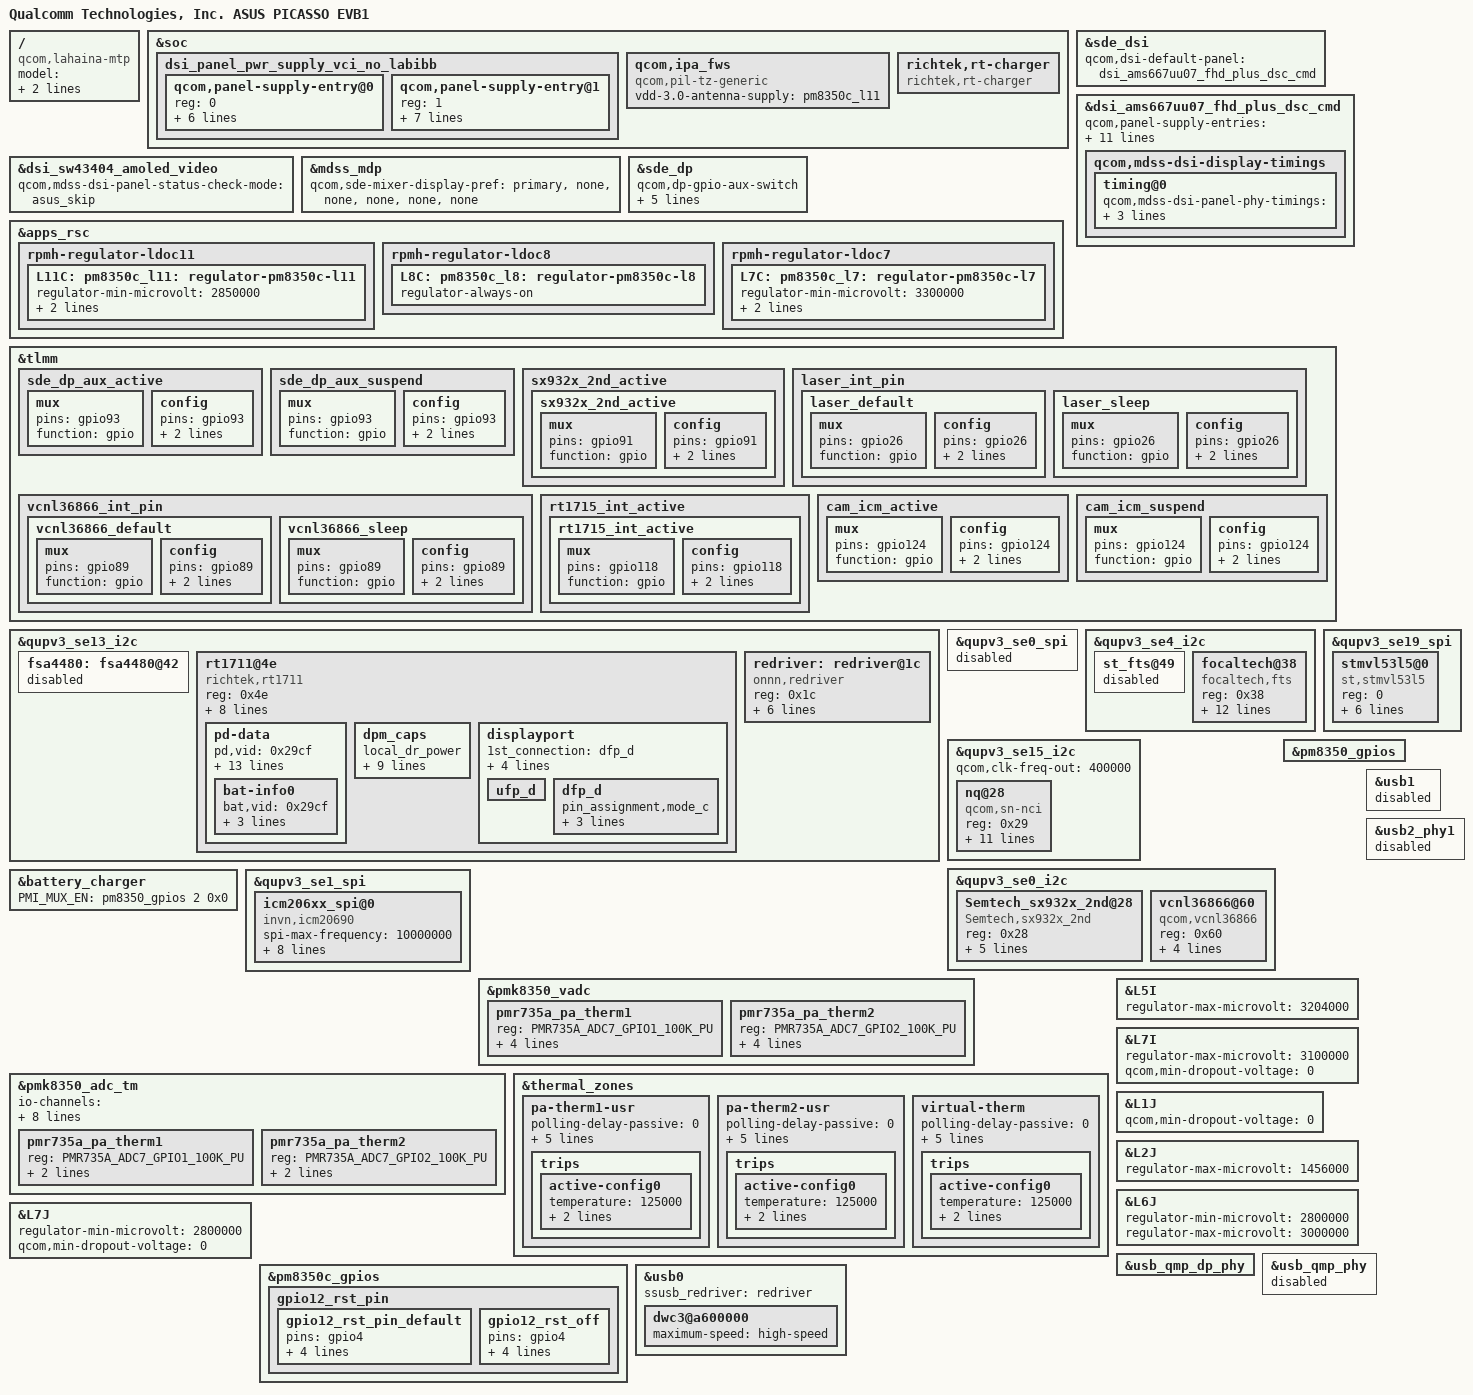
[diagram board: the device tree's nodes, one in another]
/dts-v1/;
/plugin/;

#include "lahaina-mtp.dtsi"
/* ASUS BSP Display +++ */
#include "dsi-panel-ams667uu07-fhd-plus-dsc-cmd.dtsi"

/* ASUS BSP Camera +++ */
#include "camera/zs675kw-picasso-camera-sensor-mtp.dtsi"



/ {
	model = "Qualcomm Technologies, Inc. ASUS PICASSO EVB1";
	compatible = "qcom,lahaina-mtp", "qcom,lahaina", "qcom,mtp";
	qcom,board-id = <35 0>;
};

/*   ====================================
*    overlay for display - start
*    ====================================
*/
&soc {
	dsi_panel_pwr_supply_vci_no_labibb: dsi_panel_pwr_supply_vci_no_labibb {
		#address-cells = <1>;
		#size-cells = <0>;

		qcom,panel-supply-entry@0 {
			reg = <0>;
			qcom,supply-name = "vddio";
			qcom,supply-min-voltage = <1800000>;
			qcom,supply-max-voltage = <1800000>;
			qcom,supply-enable-load = <60700>;
			qcom,supply-disable-load = <80>;
			qcom,supply-post-on-sleep = <20>;
		};

		qcom,panel-supply-entry@1 {
			reg = <1>;
			qcom,supply-name = "vdd";
			qcom,supply-min-voltage = <3000000>;
			qcom,supply-max-voltage = <3000000>;
			qcom,supply-enable-load = <10000>;
			qcom,supply-disable-load = <0>;
			qcom,supply-post-on-sleep = <0>;
			qcom,supply-pre-off-sleep = <10>;
		};
	};

};

&sde_dsi {
	/delete-property/ avdd-supply;
	qcom,dsi-default-panel = <&dsi_ams667uu07_fhd_plus_dsc_cmd>;

};

&dsi_ams667uu07_fhd_plus_dsc_cmd {
	qcom,panel-supply-entries = <&dsi_panel_pwr_supply_vci_no_labibb>;
	qcom,mdss-dsi-bl-pmic-control-type = "bl_ctrl_dcs";
	qcom,mdss-dsi-bl-min-level = <1>;
	qcom,mdss-dsi-bl-max-level = <4095>;

	qcom,platform-te-gpio = <&tlmm 82 0>; // default is 82
	qcom,platform-reset-gpio = <&tlmm 24 0>;
	qcom,platform-en-gpio = <&tlmm 80 0>;

	qcom,ulps-enabled;
	qcom,dsi-select-clocks = "mux_byte_clk0", "mux_pixel_clk0";
	qcom,mdss-dsi-display-timings {
		timing@0 {
			qcom,mdss-dsi-panel-phy-timings = [00 14 05 05 13 1E 05
				05 06 02 04 00 12 0A];
			qcom,display-topology = <2 2 1>;
			qcom,default-topology-index = <0>;
		};
	};
};

&dsi_sw43404_amoled_video {
	qcom,mdss-dsi-panel-status-check-mode = "asus_skip";
};

&mdss_mdp {
	qcom,sde-mixer-display-pref = "primary", "none", "none",
				"none", "none", "none";
};

&sde_dp {
	/delete-property/ qcom,dp-aux-switch;
	qcom,dp-gpio-aux-switch;

	qcom,aux-en-gpio = <&tlmm 93 0>;
	qcom,aux-sel-gpio = <&pm8350c_gpios 1 0x0>;
	qcom,audio-debug-gpio = <&tlmm 123 0>;

	pinctrl-names = "mdss_dp_active", "mdss_dp_sleep";
	pinctrl-0 = <&sde_dp_aux_active >;
	pinctrl-1 = <&sde_dp_aux_suspend>;
};

//ASUS_BSP RIL+++
&soc {
	qcom,ipa_fws {
		compatible = "qcom,pil-tz-generic";
		vdd-3.0-antenna-supply = <&pm8350c_l11>;
	};
};

&apps_rsc {
	rpmh-regulator-ldoc11 {
		L11C: pm8350c_l11: regulator-pm8350c-l11 {
			regulator-min-microvolt = <2850000>;
			regulator-max-microvolt = <2850000>;
			qcom,init-voltage = <2850000>;
		};
	};
};
//ASUS_BSP RIL---

&tlmm {
	/delete-property/ display_panel_avdd_default;

	sde_dp_aux_active: sde_dp_aux_active {
		mux {
			pins = "gpio93";
			function = "gpio";
		};

		config {
			pins = "gpio93";
			bias-disable = <0>; /* no pull */
			drive-strength = <8>;
		};
	};

	sde_dp_aux_suspend: sde_dp_aux_suspend {
		mux {
			pins = "gpio93";
			function = "gpio";
		};

		config {
			pins = "gpio93";
			bias-disable = <0>; /* no pull */
			drive-strength = <2>;
		};
	};
};

&qupv3_se13_i2c {
	fsa4480: fsa4480@42 {
		status = "disable";
	};
};
/*   ====================================
*    overlay for display - end
*    ====================================
*/

/*    ====================================
 *    overlay for lahainap-v2.dtsi - start
 *    ====================================
 */

/*    ====================================
 *    overlay for lahainap-v2.dtsi - end
 *    ====================================
 */



/*    ====================================
 *    overlay for lahainap.dtsi - start
 *    ====================================
 */

/*    ====================================
 *    overlay for lahainap.dtsi - end
 *    ====================================
*/



/*    ====================================
 *    overlay for lahaina-mtp.dtsi - start
 *    ====================================
 */

&qupv3_se0_spi {
	status = "disable";
};

//ASUS_BSP BerylHou +++ 
//"touch FT3658U" +++
 &qupv3_se4_i2c {
  	status = "ok";

  	st_fts@49 {
		status = "disable";
	};
  	
	focaltech@38 {
		compatible = "focaltech,fts";
		reg = <0x38>;
		interrupt-parent = <&tlmm>;
		interrupts = <23 0x2008>;
		focaltech,reset-gpio = <&tlmm 22 0x00>;
		focaltech,irq-gpio = <&tlmm 23 0x2008>;
		focaltech,vddio = <&tlmm 131 0x00>;
		focaltech,max-touch-number = <10>;
		focaltech,display-coords = <0 0 1080 2400>;

		vdd-supply = <&L3C>;
		vcc_i2c-supply = <&L8C>;

		pinctrl-names = "pmx_ts_active", "pmx_ts_suspend","pmx_ts_release";
		pinctrl-0 = <&ts_active>;
		pinctrl-1 = <&ts_int_suspend &ts_reset_suspend>;
		pinctrl-2 = <&ts_release>;

//		panel = <&dsi_ams667uu07_fhd_plus_dsc_cmd>;
//			 &dsi_r66451_amoled_video>;
	};
};
//"touch FT3658U" ---

&qupv3_se15_i2c{
	status = "ok";
	qcom,clk-freq-out = <400000>;

	nq@28 {
		compatible = "qcom,sn-nci";
		reg = <0x29>;
		qcom,sn-irq = <&tlmm 87 0x00>;
		qcom,sn-ven = <&tlmm 62 0x00>;
		qcom,sn-firm = <&tlmm 86 0x00>;
		qcom,sn-clkreq = <&tlmm 63 0x00>;
		interrupt-parent = <&tlmm>;
		interrupts = <87 0>;
		interrupt-names = "nfc_irq";
		pinctrl-names = "nfc_active", "nfc_suspend";
		pinctrl-0 = <&nfc_int_active &nfc_enable_active
				&nfc_clk_req_active &nfc_fwdl_active>;
		pinctrl-1 = <&nfc_int_suspend &nfc_enable_suspend
				&nfc_clk_req_suspend &nfc_fwdl_suspend>;
	};
};


//cap sensor 1  SX9325" +++
/* &qupv3_se15_i2c{
	status = "ok";
	Semtech_sx932x@28 {
	compatible = "Semtech,sx932x";
	reg = <0x28>;
	//interrupt-parent = <&tlmm>;
	//interrupts = <99 0>;
	pinctrl-names = "sx932x_1st_active";
	pinctrl-0 = <&sx932x_1st_active>;
		
	Semtech,nirq-gpio = <&tlmm 99 0x00>;
	status = "ok";
	Semtech,reg-num = <45>; // total registers number to initialize
	Semtech,reg-init  = /bits/ 8 < 0x10 0x1C
                                0x11 0x21
                                0x14 0x00
                                0x15 0x00
                                0x20 0x20
                                0x23 0x00
                                0x24 0x47
                                0x26 0x00
                                0x27 0x47
                                0x28 0x39
                                0x29 0x2D
                                0x2A 0x36
                                0x2B 0x07
                                0x2C 0x12
                                0x2D 0x08
                                0x30 0x21
                                0x31 0x0B
                                0x32 0x20
                                0x33 0x20
                                0x34 0x0C
                                0x35 0x00
                                0x36 0x8E
                                0x37 0xB3
                                0x40 0x00
                                0x41 0x00
                                0x42 0x00
                                0x43 0x00
                                0x44 0x00
                                0x45 0x05
                                0x46 0x00
                                0x47 0x00
                                0x48 0x00
                                0x49 0x00
                                0x4A 0x00
                                0x4B 0x00
                                0x4C 0x00
                                0x50 0x14
                                0x51 0x70
                                0x52 0x20
                                0x02 0x00
                                0x05 0x6F
                                0x06 0x00
                                0x07 0x80
                                0x08 0x01
                                0x03 0x0F>;
	};
 };
 
 &tlmm{
	sx932x_active {
		sx932x_1st_active: sx932x_1st_active {
			mux {
				pins = "gpio99";
				function = "gpio";
			};
			config {
				pins = "gpio99";
				bias-pull-up;
				drive-strength = <6>;
			};
		};
	};
  };
*/
//"cap sensor 1  SX9325" ---
//"cap sensor 2  SX9325" +++
 &qupv3_se0_i2c{
	status = "ok";
	Semtech_sx932x_2nd@28 {
	compatible = "Semtech,sx932x_2nd";
	reg = <0x28>;
	pinctrl-names = "sx932x_2nd_active";
	pinctrl-0 = <&sx932x_2nd_active>;
		
	Semtech,nirq-gpio = <&tlmm 91 0x00>;
	status = "ok";	/**/
	Semtech,reg-num = <45>; /* total registers number to initialize*/
	Semtech,reg-init  = /bits/ 8 < 0x10 0x1C
                                0x11 0x21
                                0x14 0x00
                                0x15 0x00
                                0x20 0x20
                                0x23 0x00
                                0x24 0x47
                                0x26 0x00
                                0x27 0x47
                                0x28 0x39
                                0x29 0x2D
                                0x2A 0x36
                                0x2B 0x07
                                0x2C 0x12
                                0x2D 0x08
                                0x30 0x21
                                0x31 0x0B
                                0x32 0x20
                                0x33 0x20
                                0x34 0x0C
                                0x35 0x00
                                0x36 0x8E
                                0x37 0xB3
                                0x40 0x00
                                0x41 0x00
                                0x42 0x00
                                0x43 0x00
                                0x44 0x00
                                0x45 0x05
                                0x46 0x00
                                0x47 0x00
                                0x48 0x00
                                0x49 0x00
                                0x4A 0x00
                                0x4B 0x00
                                0x4C 0x00
                                0x50 0x14
                                0x51 0x70
                                0x52 0x20
                                0x02 0x00
                                0x05 0x6F
                                0x06 0x00
                                0x07 0x80
                                0x08 0x01
                                0x03 0x0F>;
	};
};

&tlmm{
	sx932x_2nd_active {
		sx932x_2nd_active: sx932x_2nd_active {
			mux {
				pins = "gpio91";
				function = "gpio";
			};
			config {
				pins = "gpio91";
				bias-pull-up;
				drive-strength = <6>;
			};
		};
	};
};
//"cap sensor 2  SX9325" ---
//ASUS_BSP BerylHou --- 

//[+++] ASUS_BSP : Add for battery_charger
&battery_charger {
	PMI_MUX_EN = <&pm8350_gpios 2 0x0>;
};
//[---] ASUS_BSP : Add for battery_charger

// ASUS_BSP +++ ShowCai laser sensor stmvl53l5
&qupv3_se19_spi {
        status = "ok";
        stmvl53l5@0 {
                compatible = "st,stmvl53l5";
                reg = <0>;
                spi-max-frequency = <20000000>;
                laser_vdd-supply = <&pm8350c_l7>;
                laser_bus-supply = <&pm8350c_l8>;
                pinctrl-names = "laser_default", "laser_suspend";
                pinctrl-0 = <&laser_default>;
                pinctrl-1 = <&laser_sleep>;
                qcom,intr-gpio = <&tlmm 26 0x0>;
        };
};
&tlmm {
        laser_int_pin {
                laser_default: laser_default {
                        mux {
                                pins = "gpio26";
                                function = "gpio";
                        };
                                config {
                                pins = "gpio26";
                                bias-pull-up; /* No PULL */
                                drive-strength = <8>; /* 2 MA */
                        };
                };
                laser_sleep: laser_sleep {
                        mux {
                                pins = "gpio26";
                                function = "gpio";
                        };
                                config {
                                pins = "gpio26";
                                bias-pull-down; /* PULL DOWN */
                                drive-strength = <2>; /* 2 MA */
                        };
                };
        };
};
// ASUS_BSP --- ShowCai laser sensor stmvl53l5

// ASUS_BSP +++ ClayWang vcnl36866
&qupv3_se0_i2c {
        status = "ok";
            vcnl36866@60 {
			compatible = "qcom,vcnl36866";
			reg = <0x60>;
			pinctrl-names = "alsps_gpio_high","alsps_gpio_low";
			pinctrl-0 = <&vcnl36866_default>;
			pinctrl-1 = <&vcnl36866_sleep>;
			qcom,alsps-gpio = <&tlmm 89 0x0>;
			vcc_psensor-supply = <&pm8350c_l7>;
			
		};
};

&apps_rsc {
	// ASUS BSP +++ Clay vcnl36866
	rpmh-regulator-ldoc8 {
		L8C: pm8350c_l8: regulator-pm8350c-l8 {
			regulator-always-on;	/* ASUS BSP Always Enable 1.8V for I2C & Sensors */
		};
	};

	rpmh-regulator-ldoc7 {
		L7C: pm8350c_l7: regulator-pm8350c-l7 {
			regulator-min-microvolt = <3300000>;
			regulator-max-microvolt = <3300000>;
			qcom,init-voltage = <3300000>;
		};
	};
	// ASUS BSP --- Clay vcnl36866
};

&tlmm {	
	// ASUS_BSP +++ ClayWang vcnl36866
	vcnl36866_int_pin {
		vcnl36866_default: vcnl36866_default {
			mux {
				pins = "gpio89";
				function = "gpio";
			};
				config {
				pins = "gpio89";
				bias-pull-up;
				drive-strength = <6>;
			};
		};
			vcnl36866_sleep: vcnl36866_sleep {
			mux {
				pins = "gpio89";
				function = "gpio";
			};
				config {
				pins = "gpio89";
				bias-pull-up;
				drive-strength = <6>;
			};
		};
	};
	// ASUS_BSP --- ClayWang vcnl36866
};
// ASUS_BSP --- ClayWang vcnl36866

//ASUS BSP Richtek TypeC PD +++
&qupv3_se13_i2c {
	status = "ok";
	rt1711@4e {
		compatible = "richtek,rt1711";
		reg = <0x4e>;
		rt1711,irq_pin = <&tlmm 118 0x00>;
		rt-dual,supported_modes = <0>; /* 0: dfp/ufp, 1: dfp, 2: ufp */
		rt-tcpc,name = "type_c_port0"; /* tcpc_device's name */
		rt-tcpc,role_def = <4>; /* 0: SNK Only, 1: SRC Only, 2: DRP, 3: Try.SRC, 4: Try.SNK */
		rt-tcpc,rp_level = <0>; /* 0: Default, 1: 1.5, 2: 3.0 */
		rt-tcpc,vconn_supply  = <1>;  /* 0: Never, 1: Always, 2: EMarkOnly, 3: StartOnly */
		rt-tcpc,notifier_supply_num = <1>; /* the number of notifier supply */
		pinctrl-names = "rt1715_int_active";
		pinctrl-0 = <&rt1715_int_active>;
		pd-data {
			pd,vid = <0x29cf>;
			pd,pid = <0x5081>;
			pd,source-cap-ext = <0x171129cf 0x00000000 0x00000102 0x00000000 0x00000000 0x02000000>;
			pd,mfrs = "RichtekTCPC";

			/*
			 *	VSAFE5V = 0, MAX_POWER = 1, CUSTOM = 2,
			 *	MAX_POWER_LV = 0x21, MAX_POWER_LVIC = 0x31
			 *	MAX_POWER_HV = 0x41, MAX_POWER_HVIC = 0x51
			 */
				pd,charging_policy= <0x21>;

			/*
			 * Fixed 5V, 500 mA <0x00019032>
			 * Fixed 5V, 1A <0x00019064>
			 * Fixed 5V, 2A <0x000190c8>
			 * Fixed 5V, 3A <0x0001912c>
			 * Fixed 9V, 500 mA <0x0002d032>
			 * Fixed 9V, 1A <0x0002d064>
			 * Fixed 9V, 2A <0x0002d0c8>
			 * Fixed 9V, 3A <0x0002d12c>
			 * Variable 5-9V, 1A <0x8642d064>
			 * Variable 5-9V, 2A <0x8642d0c8>
			 * Variable 5-9V, 3A <0x8642d12c>
			 * PPS 3V~5.9V, 3A <0xC0761E3C>
			 */
				pd,source-pdo-size = <1>;
				pd,source-pdo-data = <0x00019032>; /* 5V, 500 mA */
				pd,sink-pdo-size = <2>;
				pd,sink-pdo-data = <0x000190c8 0x000190c8> ;   /* 0x0002d0c8 : 9V, 2A<0x04019032 0x04019064> */

			/*
			 * No DP, host + device
			 *	pd,id-vdo-size = <3>;
					pd,id-vdo-data = <0xd00029cf 0x0 0x00010000>;
			 * With DP
			 *	pd,id-vdo-size = <4>;
					pd,id-vdo-data = <0xec0029cf 0x0 0x00010000 0x11000001>;
			 */

				pd,id-vdo-size = <3>;
				pd,id-vdo-data = <0xd00029cf 0x0 0x00010000>;

			bat,nr = <1>;
			pd,country_nr = <0>;

			bat-info0 {
				bat,vid = <0x29cf>;
				bat,pid = <0x1711>;
				bat,mfrs = "bat1";
				bat,design_cap = <3000>;
			};

			//bat-info1 {
			//	bat,vid = <0x8abc>;
			//	bat,pid = <0x5234>;
			//	bat,mfrs = "bat2";
			//	bat,design_cap = <4000>;
			//};

			//country0 {
			//	pd,country_code = <0x5457>;
			//	pd,country_len = <2>; /* max len = 26 */
			//	pd,country_data = <0xff 0xff>;
			//};

			//country1 {
			//	pd,country_code = <0x5553>;
			//	pd,country_len = <3>; /* max len = 26 */
			//	pd,country_data = <0xf1 0xf2 0xf3>;
			//};
		};

		dpm_caps {
			local_dr_power;
			local_dr_data;
			//local_ext_power;
			local_usb_comm;
			//local_usb_suspend;
			//local_high_cap;
			//local_give_back;
			local_no_suspend;
			local_vconn_supply;

			//attemp_discover_cable_dfp;
			attemp_enter_dp_mode;
			//attemp_discover_cable;
			attemp_discover_id;
			/* 0: disable, 1: prefer_snk, 2: prefer_src */
			pr_check = <0>;
			//pr_reject_as_source;
			//pr_reject_as_sink;
			pr_check_gp_source;
			//pr_check_gp_sink;

			/* 0: disable, 1: prefer_ufp, 2: prefer_dfp */
			dr_check = <0>;
			//dr_reject_as_dfp;
			//dr_reject_as_ufp;
		};
		displayport {
			/* connection type = "both", "ufp_d", "dfp_d" */
			1st_connection = "dfp_d";
			2nd_connection = "dfp_d";
			signal,dp_v13;
			//signal,dp_gen2;
			usbr20_not_used;
			typec,receptacle;
			ufp_d {
				//pin_assignment,mode_a;
				//pin_assignment,mode_b;
				//pin_assignment,mode_c;
				//pin_assignment,mode_d;
				//pin_assignment,mode_e;
			};
			dfp_d {
				/* Only support mode C & D */
				//pin_assignment,mode_a;
				//pin_assignment,mode_b;
				pin_assignment,mode_c;
				pin_assignment,mode_d;
				pin_assignment,mode_e;
				pin_assignment,mode_f;
			};
		};
	};
};


/* ASUS_BSP +++ icm20690 */
&qupv3_se1_spi {
	status = "ok";
        icm206xx_spi@0 {
                spi-max-frequency = <10000000>;
                compatible = "invn,icm20690";
                reg = <0x0>;
                invn,gpio-int = <&tlmm 7 1>;
                invn,use-interrupt;
                invn,place = "Portrait Down Back Side";
                icm206xx-supply = <&pm8008j_l7>;
                icm206xx-vdd-supply = <&pm8008j_l5>;
                pinctrl-names = "cam_default", "cam_suspend";
                pinctrl-0 = <&cam_icm_active>;
                pinctrl-1 = <&cam_icm_suspend>;
        };
};
/* ASUS_BSP --- icm20690 */

&soc {
	richtek,rt-charger {
	    compatible = "richtek,rt-charger";
	    //vconn-supply = <&vconn_5v>;
	};
};
//ASUS BSP Richtek TypeC PD ---

&tlmm {
	//ASUS BSP Richtek TypeC PD +++
	rt1715_int_active {
		rt1715_int_active: rt1715_int_active {
			mux {
				pins = "gpio118";
				function = "gpio";
			};

			config {
				pins = "gpio118";
				drive-strength = <2>;
				bias-pull-up;
			};
		};
	};
	//ASUS BSP Richtek TypeC PD ---
	/* ASUS_BSP +++ icm20690 */
	cam_icm_active: cam_icm_active {
		mux {
			pins = "gpio124";
			function = "gpio";
		};

		config {
			pins = "gpio124";
			bias-pull-up;
			drive-strength = <8>;
		};
	};

	cam_icm_suspend: cam_icm_suspend {
		mux {
			pins = "gpio124";
			function = "gpio";
		};

		config {
			pins = "gpio124";
			bias-pull-down;
			drive-strength = <2>; 
		};
	};
	/* ASUS_BSP --- icm20690 */
};

&qupv3_se13_i2c {
	status = "ok";

	redriver: redriver@1c {
		compatible = "onnn,redriver";
		reg = <0x1c>;

		pinctrl-names = "enable_gpio";
		pinctrl-0 = <&usb3phy_portselect_gpio>;
		orientation_gpio = <&tlmm 81 0>;

		eq = /bits/ 8 <
				/* Parameters for USB */
				0x4 0x4 0x4 0x4
				/* Parameters for DP */
				0x6 0x4 0x4 0x6>;
		flat-gain = /bits/ 8 <
				/* Parameters for USB */
				0x3 0x1 0x1 0x3
				/* Parameters for DP */
				0x2 0x1 0x1 0x2>;
		output-comp = /bits/ 8 <
				/* Parameters for USB */
				0x3 0x3 0x3 0x3
				/* Parameters for DP */
				0x3 0x3 0x3 0x3>;
		loss-match = /bits/ 8 <
				/* Parameters for USB */
				0x1 0x3 0x3 0x1
				/* Parameters for DP */
				0x3 0x3 0x3 0x3>;
	};
};

/*    ====================================
 *    overlay for lahaina-mtp.dtsi - end
 *    ====================================
 */


/*    ====================================
 *    overlay for lahaina-pm.dtsi - start
 *    ====================================
 */

/*    ====================================
 *    overlay for lahaina-pm.dtsi - end
 *    ====================================
 */



/*    ====================================
 *    overlay for lahaina-pinctrl.dtsi - start
 *    ====================================
 */

/*    ====================================
 *    overlay for lahaina-pinctrl.dtsi - end
 *    ====================================
 */



/*    ====================================
 *    overlay for lahaina-pmic-overlay.dtsi - start
 *    ====================================
 */
 
//[+++] ASUS_BSP : Don't use GPIO1 of PMIC8350 for cam
//#if 0
&pm8350_gpios {
	/delete-node/ pm8350_rear_tof_therm;	
};
&pmk8350_vadc {
	/delete-property/ pinctrl-0;
	/delete-node/ pm8350_rear_tof_therm;
	/delete-node/ pm8350_wide_rfc_therm;

	pmr735a_pa_therm1 {
		reg = <PMR735A_ADC7_GPIO1_100K_PU>;
		label = "pmr735a_pa_therm1";
		qcom,ratiometric;
		qcom,hw-settle-time = <200>;
		qcom,pre-scaling = <1 1>;
	};
	pmr735a_pa_therm2 {
		reg = <PMR735A_ADC7_GPIO2_100K_PU>;
		label = "pmr735a_pa_therm2";
		qcom,ratiometric;
		qcom,hw-settle-time = <200>;
		qcom,pre-scaling = <1 1>;
	};
};
&pmk8350_adc_tm {

	io-channels = <&pmk8350_vadc PM8350_ADC7_AMUX_THM1_100K_PU>,
			<&pmk8350_vadc PM8350_ADC7_AMUX_THM2_100K_PU>,
			<&pmk8350_vadc PM8350_ADC7_AMUX_THM3_100K_PU>,
			<&pmk8350_vadc PM8350B_ADC7_AMUX_THM4_100K_PU>,
			<&pmk8350_vadc PM8350B_ADC7_GPIO2_100K_PU>,
			<&pmk8350_vadc PMK8350_ADC7_AMUX_THM1_100K_PU>,
			<&pmk8350_vadc PMR735A_ADC7_GPIO1_100K_PU>,
			<&pmk8350_vadc PMR735A_ADC7_GPIO2_100K_PU>;

	/delete-node/ pm8350_rear_tof_therm;
	/delete-node/ pm8350_wide_rfc_therm;

	pmr735a_pa_therm1 {
		reg = <PMR735A_ADC7_GPIO1_100K_PU>;
		qcom,ratiometric;
		qcom,hw-settle-time = <200>;
	};

	pmr735a_pa_therm2 {
		reg = <PMR735A_ADC7_GPIO2_100K_PU>;
		qcom,ratiometric;
		qcom,hw-settle-time = <200>;
	};
};

&thermal_zones {
	/delete-node/ rear-cam-therm-usr;
	/delete-node/ tof-therm-usr;

	pa-therm1-usr {
		polling-delay-passive = <0>;
		polling-delay = <0>;
		thermal-governor = "user_space";
		thermal-sensors = <&pmk8350_adc_tm PMR735A_ADC7_GPIO1_100K_PU>;
		wake-capable-sensor;
		trips {
			active-config0 {
				temperature = <125000>;
				hysteresis = <1000>;
				type = "passive";
			};
		};
	};

	pa-therm2-usr {
		polling-delay-passive = <0>;
		polling-delay = <0>;
		thermal-governor = "user_space";
		thermal-sensors = <&pmk8350_adc_tm PMR735A_ADC7_GPIO2_100K_PU>;
		wake-capable-sensor;
		trips {
			active-config0 {
				temperature = <125000>;
				hysteresis = <1000>;
				type = "passive";
			};
		};
	};

	virtual-therm {
		polling-delay-passive = <0>;
		polling-delay = <0>;
		thermal-governor = "user_space";
		thermal-sensors = <&pmk8350_adc_tm PM8350_ADC7_AMUX_THM1_100K_PU>;
		wake-capable-sensor;
		trips {
			active-config0 {
				temperature = <125000>;
				hysteresis = <1000>;
				type = "passive";
			};
		};
	};
};

//[--] ASUS_BSP : Don't use GPIO1 of PMIC8350 for cam


//camera PM8008 setting

&L5I {
	regulator-max-microvolt = <3204000>;
};


&L7I {
	regulator-max-microvolt = <3100000>;
	qcom,min-dropout-voltage = <0>;
};

&L1J {
	qcom,min-dropout-voltage = <0>;
};

&L2J {
	regulator-max-microvolt = <1456000>;
};


&L6J {
	regulator-min-microvolt = <2800000>;
	regulator-max-microvolt = <3000000>;
};

&L7J {
	regulator-min-microvolt = <2800000>;
	qcom,min-dropout-voltage = <0>;
};




/*    ====================================
 *    overlay for lahaina-pmic-overlay.dtsi - end
 *    ====================================
 */


/*    ====================================
 *    overlay for pm8350.dtsi - start
 *    ====================================
 */

/*    ====================================
 *    overlay for pm8350.dtsi - end
 *    ====================================
 */


/*    ====================================
 *    overlay for pmk8350.dtsi - start
 *    ====================================
 */

/*    ====================================
 *    overlay for pmk8350.dtsi - end
 *    ====================================
 */

/*    ====================================
 *    overlay for pm8350b.dtsi - start
 *    ====================================
 */

/*    ====================================
 *    overlay for pm8350b.dtsi - end
 *    ====================================
 */

/*    ====================================
 *    overlay for pm8350c.dtsi - start
 *    ====================================
 */

&pm8350c_gpios {
	gpio12_rst_pin {
		gpio12_rst_pin_default: gpio12_rst_pin_default {
			pins = "gpio4"; 
			function = "normal"; 
			power-source = <0>; 
			output-low; 
			input-disable;
		};
		
		gpio12_rst_off: gpio12_rst_off {
			pins = "gpio4"; 
			function = "normal"; 
			bias-disable;
			output-low; 
			power-source = <0>; 
		};
	};
};

/*    ====================================
 *    overlay for pm8350c.dtsi - end
 *    ====================================
 */


/*    ====================================
 *    overlay for lahaina-regulators.dtsi - start
 *    ====================================
 */

/*    ====================================
 *    overlay for lahaina-regulators.dtsi - end
 *    ====================================
 */
  

 
/*    ====================================
 *    overlay for lahaina-audio.dtsi - start
 *    ====================================
 */

/*    ====================================
 *    overlay for lahaina-audio.dtsi - end
 *    ====================================
 */

/*    ====================================
 *    overlay for lahaina-audio-overlay.dtsi - start
 *    ====================================
 */

/*    ====================================
 *    overlay for lahaina-audio-overlay.dtsi - end
 *    ====================================
 */


/*    ====================================
 *    overlay for lahaina-thermal-overlay.dtsi - start
 *    ====================================
 */

/*    ====================================
 *    overlay for lahaina-thermal-overlay.dtsi - end
 *    ====================================
 */

 
/*    ====================================
 *    overlay for lahaina-gpu.dtsi - start
 *    ====================================
 */

/*    ====================================
 *    overlay for lahaina-gpu.dtsi - end
 *    ====================================
 */


/*    ====================================
 *    overlay for lahaina-usb.dtsi - start
 *    ====================================
 */
&usb_qmp_dp_phy {
	pinctrl-names = "portselect";
};

&usb0 {
	ssusb_redriver = <&redriver>;
	dwc3@a600000 {
		maximum-speed = "high-speed";
	};
};

&usb1 {
	status = "disabled";
};

&usb2_phy1 {
	status = "disabled";
};

&usb_qmp_phy {
	status = "disabled";
};
/*    ====================================
 *    overlay for lahaina-usb.dtsi - end
 *    ====================================
 */



